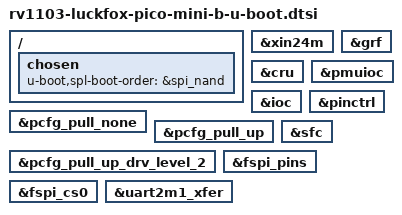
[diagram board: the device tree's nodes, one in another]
// SPDX-License-Identifier: GPL-2.0+
// (C) Copyright 2026 Simon Glass <sjg@chromium.org>

#include "rockchip-u-boot.dtsi"

/ {
	chosen {
		u-boot,spl-boot-order = &spi_nand;
	};
};

&xin24m {
	bootph-all;
};

&grf {
	bootph-all;
};

&cru {
	bootph-all;
};

&pmuioc {
	bootph-all;
};

&ioc {
	bootph-all;
};

&pinctrl {
	bootph-all;
};

&pcfg_pull_none {
	bootph-all;
};

&pcfg_pull_up {
	bootph-all;
};

&pcfg_pull_up_drv_level_2 {
	bootph-all;
};

&sfc {
	bootph-pre-ram;
	bootph-some-ram;
};

&fspi_pins {
	bootph-pre-ram;
	bootph-some-ram;
};

&fspi_cs0 {
	bootph-pre-ram;
	bootph-some-ram;
};

&uart2m1_xfer {
	bootph-all;
};
